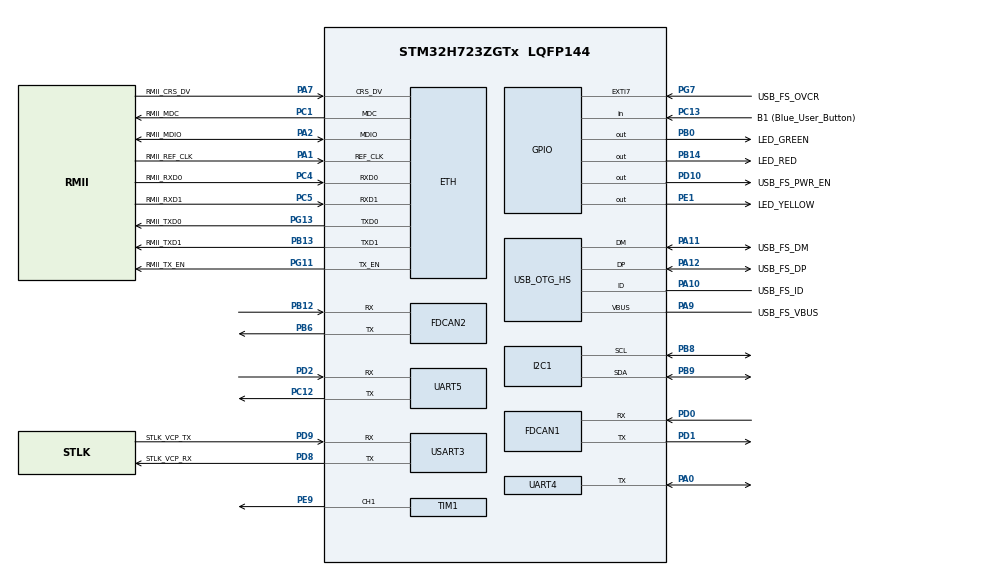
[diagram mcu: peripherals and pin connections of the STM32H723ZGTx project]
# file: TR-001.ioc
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ETH.MediaInterface=HAL_ETH_RMII_MODE
FDCAN1.CalculateBaudRateNominal=1718750
FDCAN1.CalculateTimeBitNominal=581
FDCAN1.CalculateTimeQuantumNominal=116.36363636363636
FDCAN2.CalculateBaudRateNominal=1718750
FDCAN2.CalculateTimeBitNominal=581
FDCAN2.CalculateTimeQuantumNominal=116.36363636363636
FREERTOS.Tasks01=mpu_task,0,128,mpu,Default,NULL,Dynamic,NULL,NULL;printf_task,-2,128,print_to_usb,Default,NULL,Dynamic,NULL,NULL;hip_motor_task,0,128,hip_motor,Default,NULL,Dynamic,NULL,NULL;ankle_motor_tas,0,128,ankle_motor,Default,NULL,Dynamic,NULL,NULL
FREERTOS.configUSE_NEWLIB_REENTRANT=1
I2C1.Timing=0x60404E72
Mcu.Family=STM32H7
Mcu.Name=STM32H723ZGTx
Mcu.Package=LQFP144
NVIC.I2C1_ER_IRQn=true\:5\:0\:false\:false\:true\:true\:true\:true\:true
NVIC.I2C1_EV_IRQn=true\:5\:0\:false\:false\:true\:true\:true\:true\:true
NVIC.PriorityGroup=NVIC_PRIORITYGROUP_4
NVIC.TIM6_DAC_IRQn=true\:15\:0\:false\:false\:true\:false\:false\:true\:true
NVIC.TimeBase=TIM6_DAC_IRQn
NVIC.TimeBaseIP=TIM6
NVIC.UART4_IRQn=true\:5\:0\:false\:false\:true\:true\:true\:true\:true
NVIC.UART5_IRQn=true\:5\:0\:false\:false\:true\:true\:true\:true\:true
PA0.Mode=Half_duplex(single_wire_mode)
PA0.Signal=UART4_TX
PA1.GPIO_Label=RMII_REF_CLK
PA1.Mode=RMII
PA1.Signal=ETH_REF_CLK
PA10.GPIO_Label=USB_FS_ID
PA10.Mode=OTG/Dual-Role-Device-FS
PA10.Signal=USB_OTG_HS_ID
PA11.GPIO_Label=USB_FS_DM
PA11.Mode=OTG/Dual-Role-Device-FS
PA11.Signal=USB_OTG_HS_DM
PA12.GPIO_Label=USB_FS_DP
PA12.Mode=OTG/Dual-Role-Device-FS
PA12.Signal=USB_OTG_HS_DP
PA13(JTMS/SWDIO).GPIO_Label=SWDIO
PA13(JTMS/SWDIO).Mode=Trace_Asynchronous_SW
PA13(JTMS/SWDIO).Signal=DEBUG_JTMS-SWDIO
PA14(JTCK/SWCLK).GPIO_Label=SWCLK
PA14(JTCK/SWCLK).Mode=Trace_Asynchronous_SW
PA14(JTCK/SWCLK).Signal=DEBUG_JTCK-SWCLK
PA2.GPIO_Label=RMII_MDIO
PA2.Mode=RMII
PA2.Signal=ETH_MDIO
PA7.GPIO_Label=RMII_CRS_DV
PA7.Mode=RMII
PA7.Signal=ETH_CRS_DV
PA9.GPIO_Label=USB_FS_VBUS
PA9.Mode=Activate_VBUS_FS
PA9.Signal=USB_OTG_HS_VBUS
PB0.GPIO_Label=LED_GREEN
PB0.Signal=GPIO_Output
PB12.Mode=FDCAN_Activate
PB12.Signal=FDCAN2_RX
PB13.GPIO_Label=RMII_TXD1
PB13.Mode=RMII
PB13.Signal=ETH_TXD1
PB14.GPIO_Label=LED_RED
PB14.Signal=GPIO_Output
PB3(JTDO/TRACESWO).GPIO_Label=SWO
PB3(JTDO/TRACESWO).Mode=Trace_Asynchronous_SW
PB3(JTDO/TRACESWO).Signal=DEBUG_JTDO-SWO
PB6.Mode=FDCAN_Activate
PB6.Signal=FDCAN2_TX
PB8.Mode=I2C
PB8.Signal=I2C1_SCL
PB9.Mode=I2C
PB9.Signal=I2C1_SDA
PC1.GPIO_Label=RMII_MDC
PC1.Mode=RMII
PC1.Signal=ETH_MDC
PC12.Mode=Asynchronous
PC12.Signal=UART5_TX
PC13.GPIO_Label=B1 (Blue_User_Button)
PC13.Signal=GPIO_Input
PC14-OSC32_IN.Mode=LSE-External-Oscillator
PC14-OSC32_IN.Signal=RCC_OSC32_IN
PC15-OSC32_OUT.Mode=LSE-External-Oscillator
PC15-OSC32_OUT.Signal=RCC_OSC32_OUT
PC4.GPIO_Label=RMII_RXD0
PC4.Mode=RMII
PC4.Signal=ETH_RXD0
PC5.GPIO_Label=RMII_RXD1
PC5.Mode=RMII
PC5.Signal=ETH_RXD1
PD0.Mode=FDCAN_Activate
PD0.Signal=FDCAN1_RX
PD1.Mode=FDCAN_Activate
PD1.Signal=FDCAN1_TX
PD10.GPIO_Label=USB_FS_PWR_EN
PD10.Signal=GPIO_Output
PD2.Mode=Asynchronous
PD2.Signal=UART5_RX
PD8.GPIO_Label=STLK_VCP_RX
PD8.Mode=Asynchronous
PD8.Signal=USART3_TX
PD9.GPIO_Label=STLK_VCP_TX
PD9.Mode=Asynchronous
PD9.Signal=USART3_RX
PE1.GPIO_Label=LED_YELLOW
PE1.Signal=GPIO_Output
PE9.Signal=S_TIM1_CH1
PG11.GPIO_Label=RMII_TX_EN
PG11.Mode=RMII
PG11.Signal=ETH_TX_EN
PG13.GPIO_Label=RMII_TXD0
PG13.Mode=RMII
PG13.Signal=ETH_TXD0
PG7.GPIO_Label=USB_FS_OVCR
PG7.Signal=GPXTI7
PH0-OSC_IN.GPIO_Label=MCO
PH0-OSC_IN.Mode=HSE-External-Clock-Source
PH0-OSC_IN.Signal=RCC_OSC_IN
PH1-OSC_OUT.Signal=RCC_OSC_OUT
ProjectManager.HeapSize=0x200
ProjectManager.StackSize=0x400
ProjectManager.TargetToolchain=STM32CubeIDE
RCC.ADCFreq_Value=76000000
RCC.APB1Freq_Value=137500000
RCC.APB2Freq_Value=137500000
RCC.APB3Freq_Value=137500000
RCC.APB4Freq_Value=137500000
RCC.CortexFreq_Value=550000000
RCC.D1PPRE=RCC_APB3_DIV2
RCC.D2PPRE1=RCC_APB1_DIV2
RCC.D2PPRE2=RCC_APB2_DIV2
RCC.D3PPRE=RCC_APB4_DIV2
RCC.DIVM1=4
RCC.DIVM2=1
RCC.DIVN1=275
RCC.DIVN2=19
RCC.DIVP1=1
RCC.DIVQ1=4
RCC.HCLKFreq_Value=275000000
RCC.HPRE=RCC_HCLK_DIV2
RCC.HSE_VALUE=8000000
RCC.PLLFRACN=0
RCC.PLLSourceVirtual=RCC_PLLSOURCE_HSE
RCC.SYSCLKFreq_VALUE=550000000
RCC.SYSCLKSource=RCC_SYSCLKSOURCE_PLLCLK
RCC.USBCLockSelection=RCC_USBCLKSOURCE_HSI48
RCC.USBFreq_Value=48000000
SH.S_TIM1_CH1.0=TIM1_CH1,PWM Generation1 CH1
TIM1.AutoReloadPreload=TIM_AUTORELOAD_PRELOAD_DISABLE
TIM1.Channel-PWM\ Generation1\ CH1=TIM_CHANNEL_1
TIM1.Period=3003-1
TIM1.Prescaler=200-1
UART4.AutoBaudRateEnableParam=UART_ADVFEATURE_AUTOBAUDRATE_DISABLE
USART3.VirtualMode-Asynchronous=VM_ASYNC
VP_FREERTOS_VS_CMSIS_V1.Mode=CMSIS_V1
VP_MEMORYMAP_VS_MEMORYMAP.Mode=CurAppReg
VP_SYS_VS_tim6.Mode=TIM6
VP_TIM1_VS_ClockSourceINT.Mode=Internal
board=NUCLEO-H723ZG

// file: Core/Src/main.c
/* USER CODE BEGIN Header */
/**
  ******************************************************************************
  * @file           : main.c
  * @brief          : Main program body
  ******************************************************************************
  * @attention
  *
  * Copyright (c) 2024 STMicroelectronics.
  * All rights reserved.
  *
  * This software is licensed under terms that can be found in the LICENSE file
  * in the root directory of this software component.
  * If no LICENSE file comes with this software, it is provided AS-IS.
  *
  ******************************************************************************
  */
/* USER CODE END Header */
#include "main.h"
#include "cmsis_os.h"
#include "eth.h"
#include "fdcan.h"
#include "i2c.h"
#include "memorymap.h"
#include "tim.h"
#include "usart.h"
#include "usb_otg.h"
#include "gpio.h"

/* USER CODE BEGIN Includes */
#include <stdio.h>

/* USER CODE END Includes */

void SystemClock_Config(void);
void MX_FREERTOS_Init(void);

int main(void)
{

  /* MCU Configuration--------------------------------------------------------*/

  /* Reset of all peripherals, Initializes the Flash interface and the Systick. */
  HAL_Init();

  /* Configure the system clock */
  SystemClock_Config();

  /* Initialize all configured peripherals */
  MX_GPIO_Init();
  MX_ETH_Init();
  MX_USART3_UART_Init();
  MX_USB_OTG_HS_USB_Init();
  MX_FDCAN1_Init();
  MX_I2C1_Init();
  MX_UART4_Init();
  MX_UART5_Init();
  MX_FDCAN2_Init();
  MX_TIM1_Init();

  /* Call init function for freertos objects (in cmsis_os2.c) */
  MX_FREERTOS_Init();

  /* Start scheduler */
  osKernelStart();

  /* We should never get here as control is now taken by the scheduler */

  /* Infinite loop */
  while (1)
  {

  }
}

void SystemClock_Config(void)
{
  RCC_OscInitTypeDef RCC_OscInitStruct = {0};
  RCC_ClkInitTypeDef RCC_ClkInitStruct = {0};

  /** Supply configuration update enable
  */
  HAL_PWREx_ConfigSupply(PWR_LDO_SUPPLY);

  /** Configure the main internal regulator output voltage
  */
  __HAL_PWR_VOLTAGESCALING_CONFIG(PWR_REGULATOR_VOLTAGE_SCALE0);

  while(!__HAL_PWR_GET_FLAG(PWR_FLAG_VOSRDY)) {}

  /** Initializes the RCC Oscillators according to the specified parameters
  * in the RCC_OscInitTypeDef structure.
  */
  RCC_OscInitStruct.OscillatorType = RCC_OSCILLATORTYPE_HSI48|RCC_OSCILLATORTYPE_HSE;
  RCC_OscInitStruct.HSEState = RCC_HSE_BYPASS;
  RCC_OscInitStruct.HSI48State = RCC_HSI48_ON;
  RCC_OscInitStruct.PLL.PLLState = RCC_PLL_ON;
  RCC_OscInitStruct.PLL.PLLSource = RCC_PLLSOURCE_HSE;
  RCC_OscInitStruct.PLL.PLLM = 4;
  RCC_OscInitStruct.PLL.PLLN = 275;
  RCC_OscInitStruct.PLL.PLLP = 1;
  RCC_OscInitStruct.PLL.PLLQ = 4;
  RCC_OscInitStruct.PLL.PLLR = 2;
  RCC_OscInitStruct.PLL.PLLRGE = RCC_PLL1VCIRANGE_1;
  RCC_OscInitStruct.PLL.PLLVCOSEL = RCC_PLL1VCOWIDE;
  RCC_OscInitStruct.PLL.PLLFRACN = 0;
  if (HAL_RCC_OscConfig(&RCC_OscInitStruct) != HAL_OK)
  {
    Error_Handler();
  }

  /** Initializes the CPU, AHB and APB buses clocks
  */
  RCC_ClkInitStruct.ClockType = RCC_CLOCKTYPE_HCLK|RCC_CLOCKTYPE_SYSCLK
                              |RCC_CLOCKTYPE_PCLK1|RCC_CLOCKTYPE_PCLK2
                              |RCC_CLOCKTYPE_D3PCLK1|RCC_CLOCKTYPE_D1PCLK1;
  RCC_ClkInitStruct.SYSCLKSource = RCC_SYSCLKSOURCE_PLLCLK;
  RCC_ClkInitStruct.SYSCLKDivider = RCC_SYSCLK_DIV1;
  RCC_ClkInitStruct.AHBCLKDivider = RCC_HCLK_DIV2;
  RCC_ClkInitStruct.APB3CLKDivider = RCC_APB3_DIV2;
  RCC_ClkInitStruct.APB1CLKDivider = RCC_APB1_DIV2;
  RCC_ClkInitStruct.APB2CLKDivider = RCC_APB2_DIV2;
  RCC_ClkInitStruct.APB4CLKDivider = RCC_APB4_DIV2;

  if (HAL_RCC_ClockConfig(&RCC_ClkInitStruct, FLASH_LATENCY_3) != HAL_OK)
  {
    Error_Handler();
  }
}

void HAL_TIM_PeriodElapsedCallback(TIM_HandleTypeDef *htim)
{
  if (htim->Instance == TIM6) {
    HAL_IncTick();
  }
}

void Error_Handler(void)
{
  __disable_irq();
  while (1)
  {
  }
}

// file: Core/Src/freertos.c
/* USER CODE BEGIN Header */
/**
  ******************************************************************************
  * File Name          : freertos.c
  * Description        : Code for freertos applications
  ******************************************************************************
  * @attention
  *
  * Copyright (c) 2024 STMicroelectronics.
  * All rights reserved.
  *
  * This software is licensed under terms that can be found in the LICENSE file
  * in the root directory of this software component.
  * If no LICENSE file comes with this software, it is provided AS-IS.
  *
  ******************************************************************************
  */
/* USER CODE END Header */

#include "FreeRTOS.h"
#include "task.h"
#include "main.h"
#include "cmsis_os.h"

/* USER CODE BEGIN Includes */
#include <stdio.h>
#include "printf_redir.h"
#include "mpu6050.h"
#include "hip_motors.h"
#include "ankle_motors.h"
/* USER CODE END Includes */

/* USER CODE BEGIN Variables */
mpu6050_data mpu_data;
/* USER CODE END Variables */
osThreadId mpu_taskHandle;
osThreadId printf_taskHandle;
osThreadId hip_motor_taskHandle;
osThreadId ankle_motor_tasHandle;

void mpu(void const * argument);
void print_to_usb(void const * argument);
void hip_motor(void const * argument);
void ankle_motor(void const * argument);

void MX_FREERTOS_Init(void); /* (MISRA C 2004 rule 8.1) */

/* GetIdleTaskMemory prototype (linked to static allocation support) */
void vApplicationGetIdleTaskMemory( StaticTask_t **ppxIdleTaskTCBBuffer, StackType_t **ppxIdleTaskStackBuffer, uint32_t *pulIdleTaskStackSize );

/* USER CODE BEGIN GET_IDLE_TASK_MEMORY */
static StaticTask_t xIdleTaskTCBBuffer;
static StackType_t xIdleStack[configMINIMAL_STACK_SIZE];

void vApplicationGetIdleTaskMemory( StaticTask_t **ppxIdleTaskTCBBuffer, StackType_t **ppxIdleTaskStackBuffer, uint32_t *pulIdleTaskStackSize )
{
  *ppxIdleTaskTCBBuffer = &xIdleTaskTCBBuffer;
  *ppxIdleTaskStackBuffer = &xIdleStack[0];
  *pulIdleTaskStackSize = configMINIMAL_STACK_SIZE;
  /* place for user code */
}
/* USER CODE END GET_IDLE_TASK_MEMORY */

void MX_FREERTOS_Init(void) {

  /* Create the thread(s) */
  /* definition and creation of mpu_task */
  osThreadDef(mpu_task, mpu, osPriorityNormal, 0, 128);
  mpu_taskHandle = osThreadCreate(osThread(mpu_task), NULL);

  /* definition and creation of printf_task */
  osThreadDef(printf_task, print_to_usb, osPriorityLow, 0, 128);
  printf_taskHandle = osThreadCreate(osThread(printf_task), NULL);

  /* definition and creation of hip_motor_task */
  osThreadDef(hip_motor_task, hip_motor, osPriorityNormal, 0, 128);
  hip_motor_taskHandle = osThreadCreate(osThread(hip_motor_task), NULL);

  /* definition and creation of ankle_motor_tas */
  osThreadDef(ankle_motor_tas, ankle_motor, osPriorityNormal, 0, 128);
  ankle_motor_tasHandle = osThreadCreate(osThread(ankle_motor_tas), NULL);

}

void mpu(void const * argument)
{
  /* USER CODE BEGIN mpu */
  /* Infinite loop */
  for(;;)
  {
    printf("mpu_task \r\n");
    MPU6050_update_data(&mpu_data);
  }
  /* USER CODE END mpu */
}

void print_to_usb(void const * argument)
{
  /* USER CODE BEGIN print_to_usb */
  /* Infinite loop */
  for(;;)
  {
//    printf("accel data: \r\n");
//    printf("Ax = %4.2f \r\n", mpu_data.Ax);
//    printf("Ay = %4.2f \r\n", mpu_data.Ay);
//    printf("Az = %4.2f \r\n", mpu_data.Az);
//    printf("Gx = %4.2f \r\n", mpu_data.Gx);
//    printf("Gy = %4.2f \r\n", mpu_data.Gy);
//    printf("Gz = %4.2f \r\n", mpu_data.Gz);
  }
  /* USER CODE END print_to_usb */
}

void hip_motor(void const * argument)
{
  /* USER CODE BEGIN hip_motor */
  /* Infinite loop */
  for(;;)
  {
    printf("hip motor task \r\n");
  }
  /* USER CODE END hip_motor */
}

void ankle_motor(void const * argument)
{
  /* USER CODE BEGIN ankle_motor */
  /* Infinite loop */
  for(;;)
  {
    printf("ankle motor task \r\n");
  }
  /* USER CODE END ankle_motor */
}
